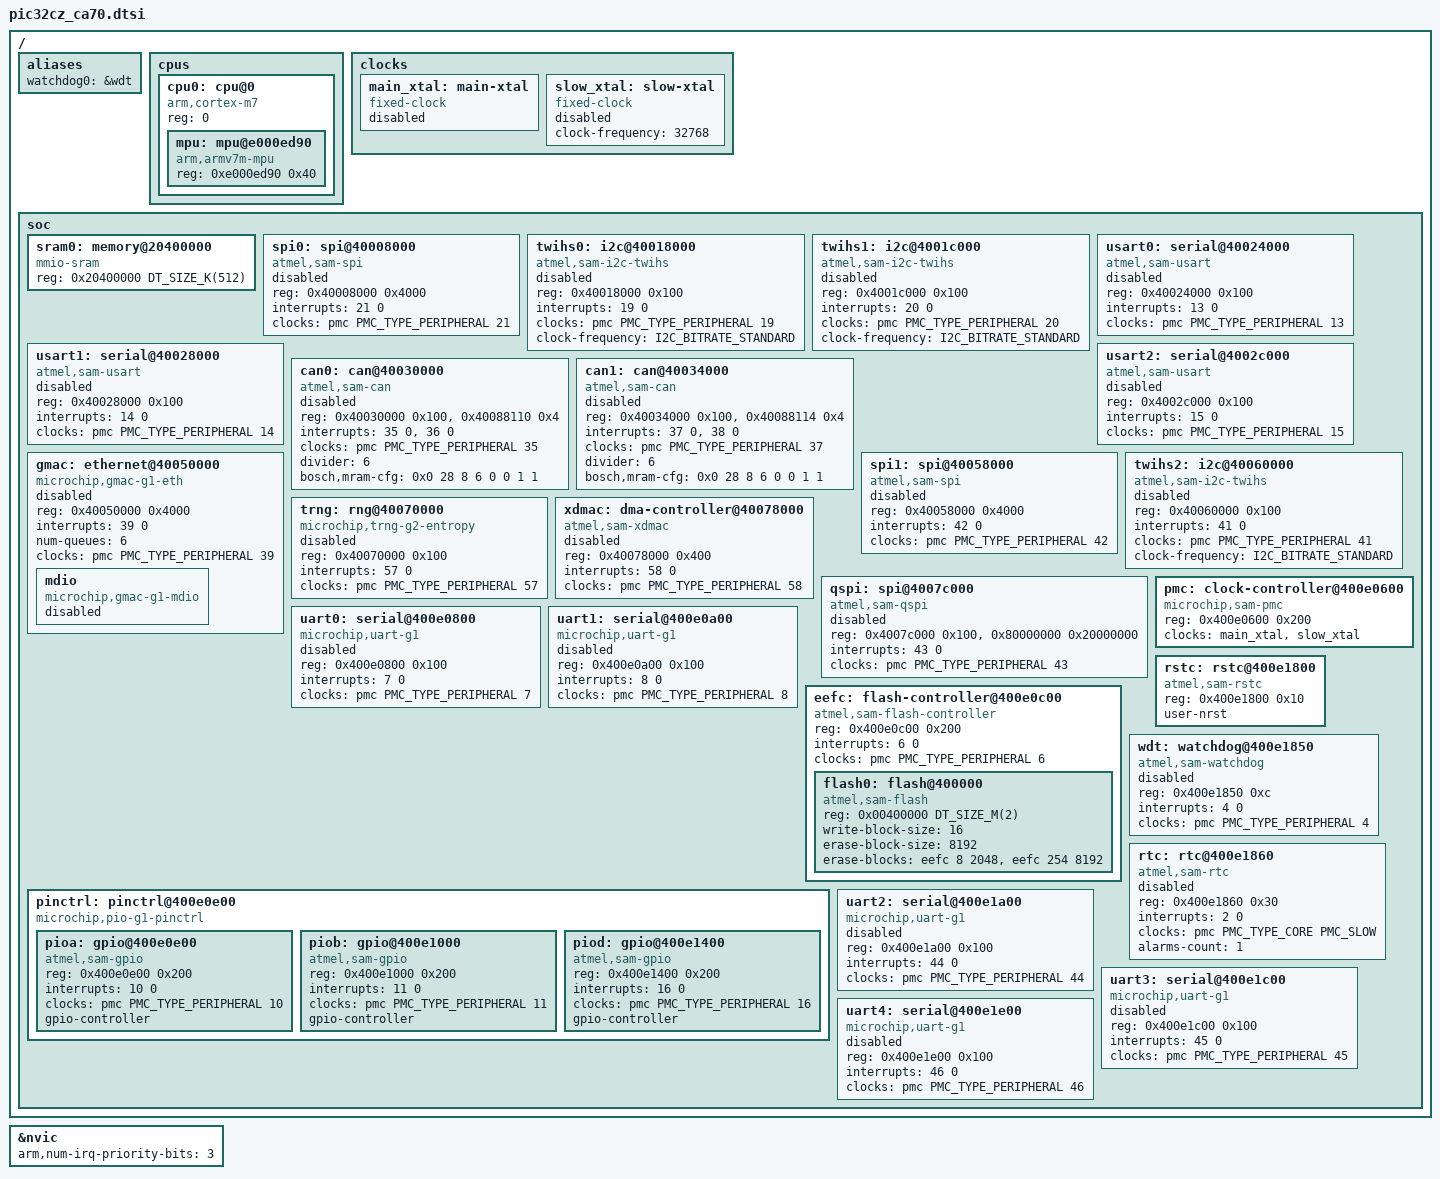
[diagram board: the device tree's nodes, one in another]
/*
 * SPDX-FileCopyrightText: Copyright The Zephyr Project Contributors
 *
 * SPDX-License-Identifier: Apache-2.0
 */

#include <arm/armv7-m.dtsi>
#include <mem.h>
#include <zephyr/dt-bindings/clock/microchip_sam_pmc.h>
#include <zephyr/dt-bindings/dma/atmel_samx7x_dma.h>
#include <zephyr/dt-bindings/gpio/gpio.h>
#include <zephyr/dt-bindings/i2c/i2c.h>

/ {
	aliases {
		watchdog0 = &wdt;
	};

	cpus {
		#address-cells = <1>;
		#size-cells = <0>;

		cpu0: cpu@0 {
			compatible = "arm,cortex-m7";
			reg = <0>;
			device_type = "cpu";
			#address-cells = <1>;
			#size-cells = <1>;

			mpu: mpu@e000ed90 {
				compatible = "arm,armv7m-mpu";
				reg = <0xe000ed90 0x40>;
			};
		};
	};

	clocks {
		main_xtal: main-xtal {
			compatible = "fixed-clock";
			#clock-cells = <0>;
			status = "disabled";
		};

		slow_xtal: slow-xtal {
			compatible = "fixed-clock";
			#clock-cells = <0>;
			clock-frequency = <32768>;
			status = "disabled";
		};
	};

	soc {
		sram0: memory@20400000 {
			compatible = "mmio-sram";
			reg = <0x20400000 DT_SIZE_K(512)>;
		};

		spi0: spi@40008000 {
			compatible = "atmel,sam-spi";
			reg = <0x40008000 0x4000>;
			#address-cells = <1>;
			#size-cells = <0>;
			interrupts = <21 0>;
			clocks = <&pmc PMC_TYPE_PERIPHERAL 21>;
			status = "disabled";
		};

		twihs0: i2c@40018000 {
			compatible = "atmel,sam-i2c-twihs";
			reg = <0x40018000 0x100>;
			interrupts = <19 0>;
			clocks = <&pmc PMC_TYPE_PERIPHERAL 19>;
			clock-frequency = <I2C_BITRATE_STANDARD>;
			#address-cells = <1>;
			#size-cells = <0>;
			status = "disabled";
		};

		twihs1: i2c@4001c000 {
			compatible = "atmel,sam-i2c-twihs";
			reg = <0x4001c000 0x100>;
			interrupts = <20 0>;
			clocks = <&pmc PMC_TYPE_PERIPHERAL 20>;
			clock-frequency = <I2C_BITRATE_STANDARD>;
			#address-cells = <1>;
			#size-cells = <0>;
			status = "disabled";
		};

		usart0: serial@40024000 {
			compatible = "atmel,sam-usart";
			reg = <0x40024000 0x100>;
			interrupts = <13 0>;
			clocks = <&pmc PMC_TYPE_PERIPHERAL 13>;
			status = "disabled";
		};

		usart1: serial@40028000 {
			compatible = "atmel,sam-usart";
			reg = <0x40028000 0x100>;
			interrupts = <14 0>;
			clocks = <&pmc PMC_TYPE_PERIPHERAL 14>;
			status = "disabled";
		};

		usart2: serial@4002c000 {
			compatible = "atmel,sam-usart";
			reg = <0x4002c000 0x100>;
			interrupts = <15 0>;
			clocks = <&pmc PMC_TYPE_PERIPHERAL 15>;
			status = "disabled";
		};

		can0: can@40030000 {
			compatible = "atmel,sam-can";
			reg = <0x40030000 0x100>, <0x40088110 0x4>;
			reg-names = "m_can", "dma_base";
			interrupts = <35 0>, <36 0>;
			interrupt-names = "int0", "int1";
			clocks = <&pmc PMC_TYPE_PERIPHERAL 35>;
			divider = <6>;
			bosch,mram-cfg = <0x0 28 8 6 0 0 1 1>;
			status = "disabled";
		};

		can1: can@40034000 {
			compatible = "atmel,sam-can";
			reg = <0x40034000 0x100>, <0x40088114 0x4>;
			reg-names = "m_can", "dma_base";
			interrupts = <37 0>, <38 0>;
			interrupt-names = "int0", "int1";
			clocks = <&pmc PMC_TYPE_PERIPHERAL 37>;
			divider = <6>;
			bosch,mram-cfg = <0x0 28 8 6 0 0 1 1>;
			status = "disabled";
		};

		gmac: ethernet@40050000 {
			compatible = "microchip,gmac-g1-eth";
			reg = <0x40050000 0x4000>;
			interrupts = <39 0>;
			interrupt-names = "gmac";
			num-queues = <6>;
			clocks = <&pmc PMC_TYPE_PERIPHERAL 39>;
			status = "disabled";

			mdio: mdio {
				compatible = "microchip,gmac-g1-mdio";
				#address-cells = <1>;
				#size-cells = <0>;
				status = "disabled";
			};
		};

		spi1: spi@40058000 {
			compatible = "atmel,sam-spi";
			reg = <0x40058000 0x4000>;
			#address-cells = <1>;
			#size-cells = <0>;
			interrupts = <42 0>;
			clocks = <&pmc PMC_TYPE_PERIPHERAL 42>;
			status = "disabled";
		};

		twihs2: i2c@40060000 {
			compatible = "atmel,sam-i2c-twihs";
			reg = <0x40060000 0x100>;
			interrupts = <41 0>;
			clocks = <&pmc PMC_TYPE_PERIPHERAL 41>;
			clock-frequency = <I2C_BITRATE_STANDARD>;
			#address-cells = <1>;
			#size-cells = <0>;
			status = "disabled";
		};

		trng: rng@40070000 {
			compatible = "microchip,trng-g2-entropy";
			reg = <0x40070000 0x100>;
			interrupts = <57 0>;
			clocks = <&pmc PMC_TYPE_PERIPHERAL 57>;
			status = "disabled";
		};

		xdmac: dma-controller@40078000 {
			compatible = "atmel,sam-xdmac";
			reg = <0x40078000 0x400>;
			interrupts = <58 0>;
			clocks = <&pmc PMC_TYPE_PERIPHERAL 58>;
			#dma-cells = <2>;
			status = "disabled";
		};

		qspi: spi@4007c000 {
			compatible = "atmel,sam-qspi";
			reg = <0x4007c000 0x100>, <0x80000000 0x20000000>;
			reg-names = "qspi", "qspi_mm";
			#address-cells = <1>;
			#size-cells = <0>;
			interrupts = <43 0>;
			clocks = <&pmc PMC_TYPE_PERIPHERAL 43>;
			status = "disabled";
		};

		pmc: clock-controller@400e0600 {
			compatible = "microchip,sam-pmc";
			reg = <0x400e0600 0x200>;
			#clock-cells = <2>;
			clocks = <&main_xtal>, <&slow_xtal>;
			clock-names = "main_xtal", "slow_xtal";
		};

		uart0: serial@400e0800 {
			compatible = "microchip,uart-g1";
			reg = <0x400e0800 0x100>;
			interrupts = <7 0>;
			clocks = <&pmc PMC_TYPE_PERIPHERAL 7>;
			status = "disabled";
		};

		uart1: serial@400e0a00 {
			compatible = "microchip,uart-g1";
			reg = <0x400e0a00 0x100>;
			interrupts = <8 0>;
			clocks = <&pmc PMC_TYPE_PERIPHERAL 8>;
			status = "disabled";
		};

		eefc: flash-controller@400e0c00 {
			compatible = "atmel,sam-flash-controller";
			reg = <0x400e0c00 0x200>;
			ranges;
			interrupts = <6 0>;
			clocks = <&pmc PMC_TYPE_PERIPHERAL 6>;
			#address-cells = <1>;
			#size-cells = <1>;
			#erase-block-cells = <2>;

			flash0: flash@400000 {
				compatible = "atmel,sam-flash", "soc-nv-flash";
				reg = <0x00400000 DT_SIZE_M(2)>;
				ranges = <0x0 0x00400000 DT_SIZE_M(2)>;
				#address-cells = <1>;
				#size-cells = <1>;
				write-block-size = <16>;
				erase-block-size = <8192>;
				erase-blocks = <&eefc 8 2048>, <&eefc 254 8192>;
			};
		};

		pinctrl: pinctrl@400e0e00 {
			compatible = "microchip,pio-g1-pinctrl";
			ranges = <0x400e0e00 0x400e0e00 0xa00>;
			#address-cells = <1>;
			#size-cells = <1>;

			pioa: gpio@400e0e00 {
				compatible = "atmel,sam-gpio";
				reg = <0x400e0e00 0x200>;
				interrupts = <10 0>;
				clocks = <&pmc PMC_TYPE_PERIPHERAL 10>;
				gpio-controller;
				#gpio-cells = <2>;
			};

			piob: gpio@400e1000 {
				compatible = "atmel,sam-gpio";
				reg = <0x400e1000 0x200>;
				interrupts = <11 0>;
				clocks = <&pmc PMC_TYPE_PERIPHERAL 11>;
				gpio-controller;
				#gpio-cells = <2>;
			};

			piod: gpio@400e1400 {
				compatible = "atmel,sam-gpio";
				reg = <0x400e1400 0x200>;
				interrupts = <16 0>;
				clocks = <&pmc PMC_TYPE_PERIPHERAL 16>;
				gpio-controller;
				#gpio-cells = <2>;
			};
		};

		rstc: rstc@400e1800 {
			compatible = "atmel,sam-rstc";
			reg = <0x400e1800 0x10>;
			user-nrst;
		};

		wdt: watchdog@400e1850 {
			compatible = "atmel,sam-watchdog";
			reg = <0x400e1850 0xc>;
			interrupts = <4 0>;
			clocks = <&pmc PMC_TYPE_PERIPHERAL 4>;
			status = "disabled";
		};

		rtc: rtc@400e1860 {
			compatible = "atmel,sam-rtc";
			reg = <0x400e1860 0x30>;
			interrupts = <2 0>;
			clocks = <&pmc PMC_TYPE_CORE PMC_SLOW>;
			alarms-count = <1>;
			status = "disabled";
		};

		uart2: serial@400e1a00 {
			compatible = "microchip,uart-g1";
			reg = <0x400e1a00 0x100>;
			interrupts = <44 0>;
			clocks = <&pmc PMC_TYPE_PERIPHERAL 44>;
			status = "disabled";
		};

		uart3: serial@400e1c00 {
			compatible = "microchip,uart-g1";
			reg = <0x400e1c00 0x100>;
			interrupts = <45 0>;
			clocks = <&pmc PMC_TYPE_PERIPHERAL 45>;
			status = "disabled";
		};

		uart4: serial@400e1e00 {
			compatible = "microchip,uart-g1";
			reg = <0x400e1e00 0x100>;
			interrupts = <46 0>;
			clocks = <&pmc PMC_TYPE_PERIPHERAL 46>;
			status = "disabled";
		};
	};
};

&nvic {
	arm,num-irq-priority-bits = <3>;
};
